# K32W061 register map
Vendor: nxp.com; File version: 1.0
CPU: CM4 r0p1, little endian, MPU, no FPU, VTOR, 3 interrupt priority bits
Registers are 32-bit, read-write, reset 0x0 unless marked. A register's access mark holds for its fields unless they carry their own. Offsets are from the block's base; [hi:lo] are bit positions; 'fields as' and 'values as' point back to an identical list.

## SPI0 — This is the description of component spi. It is a Serial Peripheral Interface with APB bus interface. More details will follow.
Base 0x4008D000; alternate view of FLEXCOMM4
Same registers: SPI1 0x4008E000 (alternate view of FLEXCOMM5)
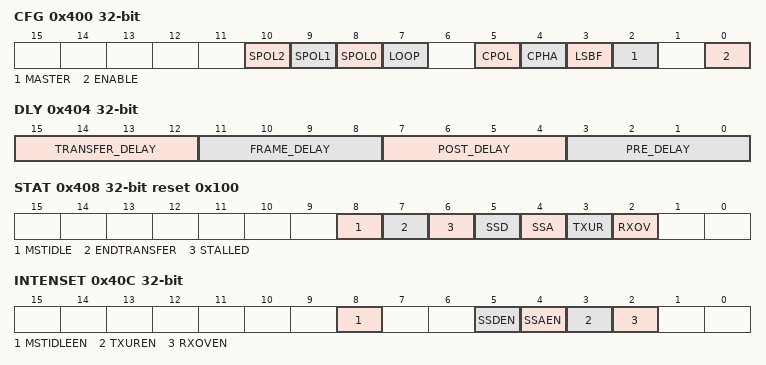
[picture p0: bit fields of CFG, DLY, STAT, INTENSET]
0x400 CFG — SPI Configuration register
  [10] SPOL2 — SSEL2 Polarity select. Valid only for SPI-1
  [9] SPOL1 — SSEL1 Polarity select. Valid only for SPI-1
  [8] SPOL0 — SSEL0 Polarity select.
  [7] LOOP — Loopback mode enable. Loopback mode applies only to Master mode, and connects transmit and receive data connected together to allow simple software testing.
  [5] CPOL — Clock Polarity select.
  [4] CPHA — Clock Phase select.
  [3] LSBF — LSB First mode enable.
  [2] MASTER — Master mode select.
  [0] ENABLE — SPI enable.
0x404 DLY — SPI Delay register
  [15:12] TRANSFER_DELAY — Controls the minimum amount of time that the SSEL is deasserted between transfers. 0x0 = The minimum time that SSEL is deasserted is 1 SPI clock time. (Zero added time.) 0x1 = The minimum time that SSEL is deasserted is 2 SPI clock times. 0x2 = The minimum time that SSEL is deasserted is 3 SPI clock times. ... 0xF = The minimum time that SSEL is deasserted is 16 SPI clock times.
  [11:8] FRAME_DELAY — If the EOFR flag is set, controls the minimum amount of time between the current frame and the next frame (or SSEL deassertion if EOTR). 0x0 = No additional time is inserted. 0x1 = 1 SPI clock time is inserted. 0x2 = 2 SPI clock times are inserted. ... 0xF = 15 SPI clock times are inserted.
  [7:4] POST_DELAY — Controls the amount of time between the end of a data transfer and SSEL deassertion. 0x0 = No additional time is inserted. 0x1 = 1 SPI clock time is inserted. 0x2 = 2 SPI clock times are inserted. ... 0xF = 15 SPI clock times are inserted.
  [3:0] PRE_DELAY — Controls the amount of time between SSEL assertion and the beginning of a data transfer. There is always one SPI clock time between SSEL assertion and the first clock edge. This is not considered part of the pre-delay. 0x0 = No additional time is inserted. 0x1 = 1 SPI clock time is inserted. 0x2 = 2 SPI clock times are inserted. ... 0xF = 15 SPI clock times are inserted.
0x408 STAT reset 0x100 — SPI Status. Some status flags can be cleared by writing a 1 to that bit position.
  [8] MSTIDLE ro — Master idle status flag. This bit is 1 whenever the SPI master function is fully idle. This means that the transmit holding register is empty and the transmitter is not in the process of sending data.
  [7] ENDTRANSFER — End Transfer control bit. Software can set this bit to force an end to the current transfer when the transmitter finishes any activity already in progress, as if the EOTR flag had been set prior to the last transmission. This capability is included to support cases where it is not known when transmit data is written that it will be the end of a transfer. The bit is cleared when the transmitter becomes idle as the transfer comes to an end. Forcing an end of transfer in this manner causes any specified FRAME_DELAY and TRANSFER_DELAY to be inserted.
  [6] STALLED ro — Stalled status flag. This indicates whether the SPI is currently in a stall condition.
  [5] SSD — Slave Select Deassert. This flag is set whenever any asserted slave selects transition to deasserted, in both master and slave modes. This allows determining when the SPI transmit/receive functions become idle. This flag is cleared by software.
  [4] SSA — Slave Select Assert. This flag is set whenever any slave select transitions from deasserted to asserted, in both master and slave modes. This allows determining when the SPI transmit/receive functions become busy, and allows waking up the device from reduced power modes when a slave mode access begins. This flag is cleared by software.
  [3] TXUR — Transmitter Underrun interrupt flag. This flag applies only to slave mode (Master = 0). In this case, the transmitter must begin sending new data on the next input clock if the transmitter is idle. If that data is not available in the transmitter holding register at that point, there is no data to transmit and the TXUR flag is set. Data transmitted by the SPI should be considered undefined if TXUR is set.
  [2] RXOV — Receiver Overrun interrupt flag. This flag applies only to slave mode (Master = 0). This flag is set when the beginning of a received character is detected while the receiver buffer is still in use. If this occurs, the receiver buffer contents are preserved, and the incoming data is lost. Data received by the SPI should be considered undefined if RxOv is set.
0x40C INTENSET — SPI Interrupt Enable read and Set. A complete value may be read from this register. Writing a 1 to any implemented bit position causes that bit to be set.
  [8] MSTIDLEEN — Master idle interrupt enable.
  [5] SSDEN — Slave select deassert interrupt enable. Determines whether an interrupt occurs when the Slave Select is deasserted.
  [4] SSAEN — Slave select assert interrupt enable. Determines whether an interrupt occurs when the Slave Select is asserted.
  [3] TXUREN — TX underrun interrupt enable. Determines whether an interrupt occurs when a transmitter underrun occurs. This happens in slave mode when there is a need to transmit data when none is available.
  [2] RXOVEN — RX overrun interrupt enable. Determines whether an interrupt occurs when a receiver overrun occurs. This happens in slave mode when there is a need for the receiver to move newly received data to the RXDAT register when it is already in use. The interface prevents receiver overrun in Master mode by not allowing a new transmission to begin when a receiver overrun would otherwise occur.
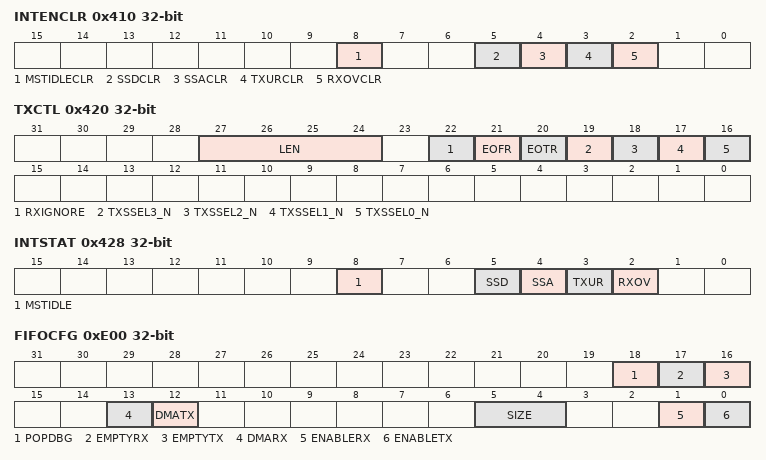
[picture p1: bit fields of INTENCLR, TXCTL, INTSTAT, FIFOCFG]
0x410 INTENCLR — SPI Interrupt Enable Clear. Writing a 1 to any implemented bit position causes the corresponding bit in INTENSET to be cleared.
  [8] MSTIDLECLR — Writing 1 clears the corresponding bit in the INTENSET register.
  [5] SSDCLR — Writing 1 clears the corresponding bit in the INTENSET register.
  [4] SSACLR — Writing 1 clears the corresponding bit in the INTENSET register.
  [3] TXURCLR — Writing 1 clears the corresponding bit in the INTENSET register.
  [2] RXOVCLR — Writing 1 clears the corresponding bit in the INTENSET register.
0x420 TXCTL — SPI Transmit Control. If Transmit FIFO is enabled, in FIFOCFG, then values read in this register are affected values in FIFO.
  [27:24] LEN — Data transfer Length.
  [22] RXIGNORE — Receive Ignore.
  [21] EOFR — End of Frame.
  [20] EOTR — End of Transfer.
  [19] TXSSEL3_N — [Reserved] Transmit Slave Select 3.
  [18] TXSSEL2_N — Transmit Slave Select 2. Valid only for SPI-1
  [17] TXSSEL1_N — Transmit Slave Select 1. Valid only for SPI-1
  [16] TXSSEL0_N — Transmit Slave Select 0.
0x424 DIV — SPI clock Divider
  [15:0] DIVVAL — Rate divider value. Specifies how the SPI Module clock is divided to produce the SPI clock rate in master mode. DIVVAL is -1 encoded such that the value 0 results in SPICLK/1, the value 1 results in SPICLK/2, up to the maximum possible divide value of 0xFFFF, which results in SPICLK/65536.
0x428 INTSTAT ro — SPI Interrupt Status
  [8] MSTIDLE — Master Idle status flag.
  [5] SSD — Slave Select Deassert.
  [4] SSA — Slave Select Assert.
  [3] TXUR — Transmitter Underrun interrupt flag.
  [2] RXOV — Receiver Overrun interrupt flag.
0xE00 FIFOCFG — FIFO configuration and enable register.
  [18] POPDBG — Pop FIFO for debug reads.
  [17] EMPTYRX — Empty command for the receive FIFO. When a 1 is written to this bit, the RX FIFO is emptied.
  [16] EMPTYTX — Empty command for the transmit FIFO. When a 1 is written to this bit, the TX FIFO is emptied.
  [13] DMARX — DMA configuration for receive.
  [12] DMATX — DMA configuration for transmit.
  [5:4] SIZE ro — FIFO size configuration. This is a read-only field. 0x0 = Reset value. 0x1 = FIFO is configured as 4 entries of 16bits. This value is read after PSELID.PERSEL=2 for SPI functionlaity. 0x2, 0x3 = not applicable.
  [1] ENABLERX — Enable the receive FIFO. This is automatically enabled when PSELID.PERSEL is set to 2 to configure for SPI functionality
  [0] ENABLETX — Enable the transmit FIFO. This is automatically enabled when PSELID.PERSEL is set to 2 to configure for SPI functionality
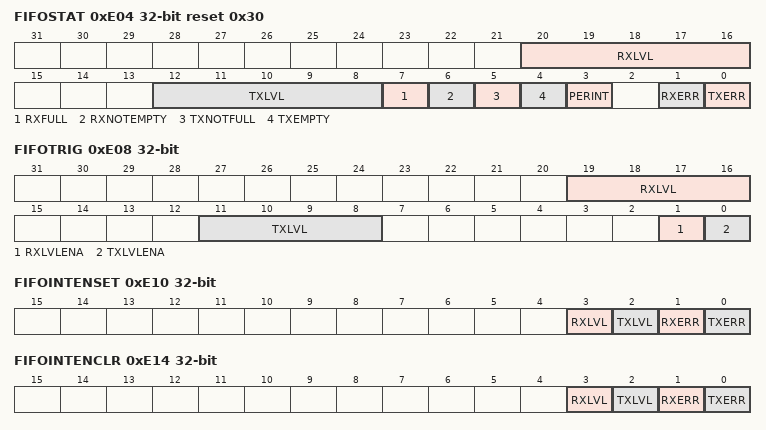
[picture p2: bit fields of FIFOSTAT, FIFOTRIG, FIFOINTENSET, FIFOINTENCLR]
0xE04 FIFOSTAT reset 0x30 — FIFO status register.
  [20:16] RXLVL ro — Receive FIFO current level. A 0 means the RX FIFO is currently empty, and the RXFULL and RXNOTEMPTY flags will be 0. Other values tell how much data is actually in the RX FIFO at the point where the read occurs. If the RX FIFO is full, the RXFULL and RXNOTEMPTY flags will be 1.
  [12:8] TXLVL ro — Transmit FIFO current level. A 0 means the TX FIFO is currently empty, and the TXEMPTY and TXNOTFULL flags will be 1. Other values tell how much data is actually in the TX FIFO at the point where the read occurs. If the TX FIFO is full, the TXEMPTY and TXNOTFULL flags will be 0.
  [7] RXFULL ro — Receive FIFO full. When 1, the receive FIFO is full. Data needs to be read out to prevent the peripheral from causing an overflow.
  [6] RXNOTEMPTY ro — Receive FIFO not empty. When 1, the receive FIFO is not empty, so data can be read. When 0, the receive FIFO is empty.
  [5] TXNOTFULL ro — Transmit FIFO not full. When 1, the transmit FIFO is not full, so more data can be written. When 0, the transmit FIFO is full and another write would cause it to overflow.
  [4] TXEMPTY ro — Transmit FIFO empty. When 1, the transmit FIFO is empty. The peripheral may still be processing the last piece of data.
  [3] PERINT ro — Peripheral interrupt. When 1, this indicates that the peripheral function has asserted an interrupt. The details can be found by reading the peripheral s STAT register.
  [1] RXERR — RX FIFO error. Will be set if a receive FIFO overflow occurs, caused by software or DMA not emptying the FIFO fast enough. Cleared by writing a 1 to this bit.
  [0] TXERR — TX FIFO error. Will be set if a transmit FIFO error occurs. This could be an overflow caused by pushing data into a full FIFO, or by an underflow if the FIFO is empty when data is needed. Cleared by writing a 1 to this bit.
0xE08 FIFOTRIG — FIFO trigger settings for interrupt and DMA request.
  [19:16] RXLVL — Receive FIFO level trigger point. The RX FIFO level is checked when a new piece of data is received. This field is used only when RXLVLENA = 1. 0 = trigger when the RX FIFO has received one entry (is no longer empty). 1 = trigger when the RX FIFO has received two entries. ... 7 = trigger when the RX FIFO has received 8 entries (has become full).
  [11:8] TXLVL — Transmit FIFO level trigger point. This field is used only when TXLVLENA = 1. 0 = trigger when the TX FIFO becomes empty. 1 = trigger when the TX FIFO level decreases to one entry. ... 7 = 1 = trigger when the TX FIFO level decreases to 7 entries (is no longer full).
  [1] RXLVLENA — Receive FIFO level trigger enable. This trigger will become an interrupt if enabled in FIFOINTENSET, or a DMA trigger if DMARX in FIFOCFG is set.
  [0] TXLVLENA — Transmit FIFO level trigger enable. This trigger will become an interrupt if enabled in FIFOINTENSET, or a DMA trigger if DMATX in FIFOCFG is set.
0xE10 FIFOINTENSET — FIFO interrupt enable set (enable) and read register.
  [3] RXLVL — Determines whether an interrupt occurs when a the receive FIFO reaches the level specified by the TXLVL field in the FIFOTRIG register.
  [2] TXLVL — Determines whether an interrupt occurs when a the transmit FIFO reaches the level specified by the TXLVL field in the FIFOTRIG register.
  [1] RXERR — Determines whether an interrupt occurs when a receive error occurs, based on the RXERR flag in the FIFOSTAT register.
  [0] TXERR — Determines whether an interrupt occurs when a transmit error occurs, based on the TXERR flag in the FIFOSTAT register.
0xE14 FIFOINTENCLR — FIFO interrupt enable clear (disable) and read register.
  [3] RXLVL — Writing 1 clears the corresponding bit in the FIFOINTENSET register
  [2] TXLVL — Writing 1 clears the corresponding bit in the FIFOINTENSET register
  [1] RXERR — Writing 1 clears the corresponding bit in the FIFOINTENSET register
  [0] TXERR — Writing 1 clears the corresponding bit in the FIFOINTENSET register
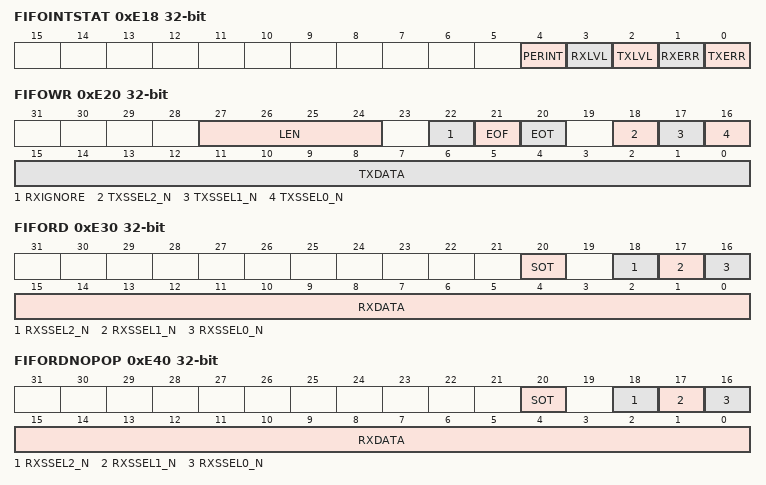
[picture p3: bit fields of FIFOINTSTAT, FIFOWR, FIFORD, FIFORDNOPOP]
0xE18 FIFOINTSTAT ro — FIFO interrupt status register.
  [4] PERINT — Peripheral interrupt.
  [3] RXLVL — Receive FIFO level interrupt.
  [2] TXLVL — Transmit FIFO level interrupt.
  [1] RXERR — RX FIFO error.
  [0] TXERR — TX FIFO error.
0xE20 FIFOWR reset not defined — FIFO write data. FIFO data not reset by block reset
  [27:24] LEN wo — Data Length. Specifies the data length from 1 to 16 bits. Note that transfer lengths greater than 16 bits are supported by implementing multiple sequential transmits. 0x0 = Data transfer is 1 bit in length. Note: when LEN = 0, the underrun status is not meaningful. 0x1 = Data transfer is 2 bits in length. 0x2 = Data transfer is 3 bits in length. ... 0xF = Data transfer is 16 bits in length.
  [22] RXIGNORE wo — Receive Ignore. This allows data to be transmitted using the SPI without the need to read unneeded data from the receiver.Setting this bit simplifies the transmit process and can be used with the DMA.
  [21] EOF wo — End of Frame. Between frames, a delay may be inserted, as defined by the FRAME_DELAY value in the DLY register. The end of a frame may not be particularly meaningful if the FRAME_DELAY value = 0. This control can be used as part of the support for frame lengths greater than 16 bits.
  [20] EOT wo — End of Transfer. The asserted SSEL will be deasserted at the end of a transfer, and remain so for at least the time specified by the Transfer_delay value in the DLY register.
  [18] TXSSEL2_N wo — Transmit Slave Select. This field asserts SSEL2 in master mode. The output on the pin is active LOW by default. Remark: The active state of the SSEL2 pin is configured by bits in the CFG register.
  [17] TXSSEL1_N wo — Transmit Slave Select. This field asserts SSEL1 in master mode. The output on the pin is active LOW by default. Remark: The active state of the SSEL1 pin is configured by bits in the CFG register.
  [16] TXSSEL0_N wo — Transmit Slave Select. This field asserts SSEL0 in master mode. The output on the pin is active LOW by default. Remark: The active state of the SSEL0 pin is configured by bits in the CFG register.
  [15:0] TXDATA wo — Transmit data to the FIFO.
0xE30 FIFORD ro — FIFO read data.
  [20] SOT — Start of Transfer flag. This flag will be 1 if this is the first data after the SSELs went from deasserted to asserted (i.e., any previous transfer has ended). This information can be used to identify the first piece of data in cases where the transfer length is greater than 16 bit.
  [18] RXSSEL2_N — Slave Select for receive. This field allows the state of the SSEL2 pin to be saved along with received data. The value will reflect the SSEL2 pin for both master and slave operation. A zero indicates that a slave select is active. The actual polarity of each slave select pin is configured by the related SPOL bit in CFG.
  [17] RXSSEL1_N — Slave Select for receive. This field allows the state of the SSEL1 pin to be saved along with received data. The value will reflect the SSEL1 pin for both master and slave operation. A zero indicates that a slave select is active. The actual polarity of each slave select pin is configured by the related SPOL bit in CFG.
  [16] RXSSEL0_N — Slave Select for receive. This field allows the state of the SSEL0 pin to be saved along with received data. The value will reflect the SSEL0 pin for both master and slave operation. A zero indicates that a slave select is active. The actual polarity of each slave select pin is configured by the related SPOL bit in CFG.
  [15:0] RXDATA — Received data from the FIFO.
0xE40 FIFORDNOPOP ro — FIFO data read with no FIFO pop.
  fields as FIFORD
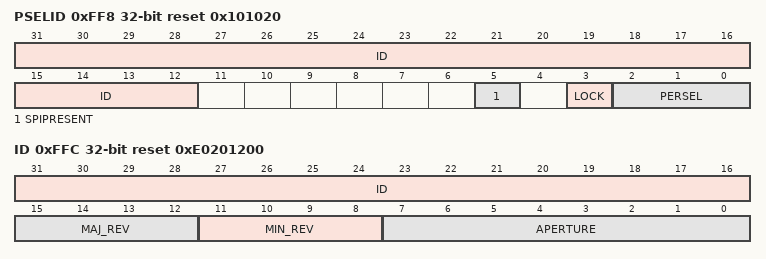
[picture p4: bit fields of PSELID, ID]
0xFF8 PSELID reset 0x101020 — Peripheral function select and ID register
  [31:12] ID ro — Peripheral Select ID.
  [5] SPIPRESENT ro — SPI present indicator. This field is Read-only and has value 0x1 to indicate SPI function is present.
  [3] LOCK — Lock the peripheral select. This field is writable by software. 0 Peripheral select can be changed by software. 1 Peripheral select is locked and cannot be changed until this peripheral or the entire device is reset.
  [2:0] PERSEL — Peripheral Select. This field is writable by software. Reset value is 0x0 showing that no peripheral is selected. Write 0x2 to select the SPI function. All other values are not valid.
0xFFC ID ro reset 0xE0201200 — SPI Module Identifier
  [31:16] ID — Identifier. This is the unique identifier of the module
  [15:12] MAJ_REV — Major revision i.e. implies software modifications
  [11:8] MIN_REV — Minor revision i.e. with no software consequences
  [7:0] APERTURE — Aperture i.e. number minus 1 of consecutive packets 4 Kbytes reserved for this IP
